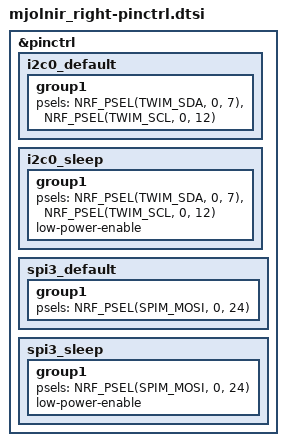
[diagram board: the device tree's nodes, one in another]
&pinctrl {
    i2c0_default: i2c0_default {
            group1 {
                    psels = <NRF_PSEL(TWIM_SDA, 0, 7)>,
                            <NRF_PSEL(TWIM_SCL, 0, 12)>;
            };
    };

    i2c0_sleep: i2c0_sleep {
            group1 {
                    psels = <NRF_PSEL(TWIM_SDA, 0, 7)>,
                            <NRF_PSEL(TWIM_SCL, 0, 12)>;
                    low-power-enable;
            };
    };


    spi3_default: spi3_default {
        group1 {
            psels = <NRF_PSEL(SPIM_MOSI, 0, 24)>;
        };
    };

    spi3_sleep: spi3_sleep {
        group1 {
            psels = <NRF_PSEL(SPIM_MOSI, 0, 24)>;
            low-power-enable;
        };
    };
};
